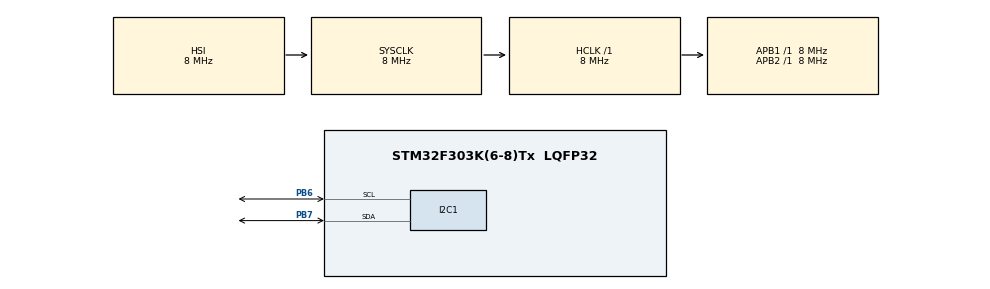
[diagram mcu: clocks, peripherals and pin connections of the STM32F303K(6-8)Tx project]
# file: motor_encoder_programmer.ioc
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I2C1.Timing=0x00201D2B
Mcu.Family=STM32F3
Mcu.Name=STM32F303K(6-8)Tx
Mcu.Package=LQFP32
NVIC.PriorityGroup=NVIC_PRIORITYGROUP_4
PA13.Mode=Serial_Wire
PA13.Signal=SYS_JTMS-SWDIO
PA14.Mode=Serial_Wire
PA14.Signal=SYS_JTCK-SWCLK
PB6.GPIO_Pu=GPIO_PULLUP
PB6.Mode=I2C
PB6.Signal=I2C1_SCL
PB7.GPIO_Pu=GPIO_PULLUP
PB7.Mode=I2C
PB7.Signal=I2C1_SDA
ProjectManager.HeapSize=0x200
ProjectManager.StackSize=0x400
ProjectManager.TargetToolchain=STM32CubeIDE
RCC.AHBFreq_Value=8000000
RCC.APB1Freq_Value=8000000
RCC.APB2Freq_Value=8000000
RCC.CortexFreq_Value=8000000
RCC.HSE_VALUE=8000000
RCC.HSI_VALUE=8000000
RCC.SYSCLKFreq_VALUE=8000000
board=custom

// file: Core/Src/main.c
/* USER CODE BEGIN Header */
/**
 ******************************************************************************
 * @file           : main.c
 * @brief          : Main program body
 ******************************************************************************
 * @attention
 *
 * Copyright (c) 2025 STMicroelectronics.
 * All rights reserved.
 *
 * This software is licensed under terms that can be found in the LICENSE file
 * in the root directory of this software component.
 * If no LICENSE file comes with this software, it is provided AS-IS.
 *
 ******************************************************************************
 */
/* USER CODE END Header */
#include "main.h"

/* USER CODE BEGIN Includes */
#include <string.h>
#include <stdlib.h>
/* USER CODE END Includes */

I2C_HandleTypeDef hi2c1;

void SystemClock_Config(void);
static void MX_GPIO_Init(void);
static void MX_I2C1_Init(void);
/* USER CODE BEGIN PFP */
HAL_StatusTypeDef i2c_Write_Encoder(I2C_HandleTypeDef *hi2c, uint16_t DevAddress, uint8_t MemAddress, uint8_t *pData, uint16_t len);  // <-- Add this line here
HAL_StatusTypeDef i2c_Read_Encoder(I2C_HandleTypeDef *hi2c, uint16_t DevAddress, uint8_t regAddress, uint8_t *pData, uint16_t len);
/* USER CODE END PFP */

int main(void)
{

  /* MCU Configuration--------------------------------------------------------*/

  /* Reset of all peripherals, Initializes the Flash interface and the Systick. */
   HAL_Init();

  /* Configure the system clock */
  SystemClock_Config();

  /* Initialize all configured peripherals */
  MX_GPIO_Init();
  MX_I2C1_Init();
  /* USER CODE BEGIN 2 */
	//const char wmsg[]="WeloveSTM32!";

  	uint8_t angle_data[] = {0x00, 0x00}; //Angle data buffer, read angle data into this buffer and also write to registers with this buffer for programming
  	uint8_t rmsg[20]; //received message buffer, randomly used

	//HAL i2c notes:
	//address of encoder device is 0110110, but we shift it to left because the transmit and receive functions require that. So we are left with 0x6C
	//Argument to right of 0x6C is the register address, see the register description in onenote.
  	//After reading from registers, the register address is incremented except for these registers: ANGLE, RAW ANGLE and MAGNITUDE Registers
  	//If you read from the ANGLE register (0x0E,0X0F), you get a decimal from 0 to 4095, 0x000 to 0xFFF in Hex (4096 total values). You have to scale that into 0 to 360.
	//i2c_Write_Encoder(&hi2c1, 0x6C, 0x08, (uint8_t*)data, sizeof(data) / sizeof(data[0]));

  	//Readout contents of registers
	i2c_Read_Encoder(&hi2c1, 0x6C, 0x00, (uint8_t*)rmsg, 1); //ZMCO, amount of times programmed angle
	i2c_Read_Encoder(&hi2c1, 0x6C, 0x01, (uint8_t*)rmsg, 2); //ZPOS, starting pos
	i2c_Read_Encoder(&hi2c1, 0x6C, 0x03, (uint8_t*)rmsg, 2); //MPOS, stop pos
	i2c_Read_Encoder(&hi2c1, 0x6C, 0x05, (uint8_t*)rmsg, 2); //MANG, maximum angle
	i2c_Read_Encoder(&hi2c1, 0x6C, 0x07, (uint8_t*)rmsg, 2); //Conf, configuration register
	i2c_Read_Encoder(&hi2c1, 0x6C, 0x0C, (uint8_t*)rmsg, 2); //Raw Angle
	i2c_Read_Encoder(&hi2c1, 0x6C, 0x0E, (uint8_t*)rmsg, 2); //Angle
	i2c_Read_Encoder(&hi2c1, 0x6C, 0x0B, (uint8_t*)rmsg, 1); //Status
	i2c_Read_Encoder(&hi2c1, 0x6C, 0x1A, (uint8_t*)rmsg, 1); //AGC, Automatic Gain Control, The AGC range is reduced to 0-128 counts in 3.3V mode.
	i2c_Read_Encoder(&hi2c1, 0x6C, 0x1B, (uint8_t*)rmsg, 2); //Magnitude: magnitude value of the internal CORDIC

//	//Angle Programming through I2C interface (Option A in datasheet)
//	//Run in debug mode, make sure to do the 3.3V wiring in fig.  38
//	//Turn angle to starting position
//	i2c_Read_Encoder(&hi2c1, 0x6C, 0x0C, (uint8_t*)angle_data, 2); //Read From starting position Raw Angle, store result in first two bytes of angle_data
//	i2c_Write_Encoder(&hi2c1, 0x6C, 0x01, (uint8_t*)angle_data, 2); //Write the starting position raw angle into ZPOS register
//	//Now rotate the magnet to the stop position
//	i2c_Read_Encoder(&hi2c1, 0x6C, 0x0C, (uint8_t*)angle_data, 2); //Read From starting position Raw Angle, store result in first two bytes of angle_data
//	i2c_Write_Encoder(&hi2c1, 0x6C, 0x03, (uint8_t*)angle_data, 2); //Write the starting position raw angle into MPOS register
//	//Burning the settings to "permanently" program the magnetic encoder.
//	uint8_t command_buffer[] = {0x00, 0x00, 0x00};
//	command_buffer[0] = 0x80; //BURN_ANGLE command
//	i2c_Write_Encoder(&hi2c1, 0x6C, 0xFF, (uint8_t*)command_buffer, 1); //Perform a BURN_ANGLE command by writing 0x80 value into 0xFF register
//	//Verify burn command
//	memcpy(command_buffer, ((uint8_t[3]){0x01, 0x11, 0x10}), 3 * sizeof(uint8_t)); //load the buffer with 3 commands, replaces the entire buffer
//	i2c_Write_Encoder(&hi2c1, 0x6C, 0xFF, (uint8_t*)command_buffer, 3); //Writing these 3 commands sequentially into 0xFF register to load actual OTP non-volatile memory content
//	//Read ZPOS and MPOS registers to verify the BURN_ANGLE command was successful
//	i2c_Read_Encoder(&hi2c1, 0x6C, 0x01, (uint8_t*)rmsg, 2); //ZPOS, starting pos
//	i2c_Read_Encoder(&hi2c1, 0x6C, 0x03, (uint8_t*)rmsg, 2); //MPOS, stop pos
//	//Might want to do power up cycle and reread the ZPOS and MPOS registers again to make sure they match with new positions

	//Programming to turn on PWM mode by modifying CONF register on magnetic encoder.
	i2c_Read_Encoder(&hi2c1, 0x6C, 0x07, (uint8_t*)rmsg, 2);
	i2c_Write_Encoder(&hi2c1, 0x6C, 0x01, (uint8_t*)angle_data, 2);
  /* USER CODE END 2 */

  /* Infinite loop */
	while (1)
	{

	}
}

void SystemClock_Config(void)
{
  RCC_OscInitTypeDef RCC_OscInitStruct = {0};
  RCC_ClkInitTypeDef RCC_ClkInitStruct = {0};
  RCC_PeriphCLKInitTypeDef PeriphClkInit = {0};

  /** Initializes the RCC Oscillators according to the specified parameters
  * in the RCC_OscInitTypeDef structure.
  */
  RCC_OscInitStruct.OscillatorType = RCC_OSCILLATORTYPE_HSI;
  RCC_OscInitStruct.HSIState = RCC_HSI_ON;
  RCC_OscInitStruct.HSICalibrationValue = RCC_HSICALIBRATION_DEFAULT;
  RCC_OscInitStruct.PLL.PLLState = RCC_PLL_NONE;
  if (HAL_RCC_OscConfig(&RCC_OscInitStruct) != HAL_OK)
  {
    Error_Handler();
  }

  /** Initializes the CPU, AHB and APB buses clocks
  */
  RCC_ClkInitStruct.ClockType = RCC_CLOCKTYPE_HCLK|RCC_CLOCKTYPE_SYSCLK
                              |RCC_CLOCKTYPE_PCLK1|RCC_CLOCKTYPE_PCLK2;
  RCC_ClkInitStruct.SYSCLKSource = RCC_SYSCLKSOURCE_HSI;
  RCC_ClkInitStruct.AHBCLKDivider = RCC_SYSCLK_DIV1;
  RCC_ClkInitStruct.APB1CLKDivider = RCC_HCLK_DIV1;
  RCC_ClkInitStruct.APB2CLKDivider = RCC_HCLK_DIV1;

  if (HAL_RCC_ClockConfig(&RCC_ClkInitStruct, FLASH_LATENCY_0) != HAL_OK)
  {
    Error_Handler();
  }
  PeriphClkInit.PeriphClockSelection = RCC_PERIPHCLK_I2C1;
  PeriphClkInit.I2c1ClockSelection = RCC_I2C1CLKSOURCE_HSI;
  if (HAL_RCCEx_PeriphCLKConfig(&PeriphClkInit) != HAL_OK)
  {
    Error_Handler();
  }
}

static void MX_I2C1_Init(void)
{

  hi2c1.Instance = I2C1;
  hi2c1.Init.Timing = 0x00201D2B;
  hi2c1.Init.OwnAddress1 = 0;
  hi2c1.Init.AddressingMode = I2C_ADDRESSINGMODE_7BIT;
  hi2c1.Init.DualAddressMode = I2C_DUALADDRESS_DISABLE;
  hi2c1.Init.OwnAddress2 = 0;
  hi2c1.Init.OwnAddress2Masks = I2C_OA2_NOMASK;
  hi2c1.Init.GeneralCallMode = I2C_GENERALCALL_DISABLE;
  hi2c1.Init.NoStretchMode = I2C_NOSTRETCH_DISABLE;
  if (HAL_I2C_Init(&hi2c1) != HAL_OK)
  {
    Error_Handler();
  }

  /** Configure Analogue filter
  */
  if (HAL_I2CEx_ConfigAnalogFilter(&hi2c1, I2C_ANALOGFILTER_ENABLE) != HAL_OK)
  {
    Error_Handler();
  }

  /** Configure Digital filter
  */
  if (HAL_I2CEx_ConfigDigitalFilter(&hi2c1, 0) != HAL_OK)
  {
    Error_Handler();
  }

}

static void MX_GPIO_Init(void)
{

  /* GPIO Ports Clock Enable */
  __HAL_RCC_GPIOA_CLK_ENABLE();
  __HAL_RCC_GPIOB_CLK_ENABLE();

}

/* USER CODE BEGIN 4 */
HAL_StatusTypeDef i2c_Read_Encoder(I2C_HandleTypeDef *hi2c, uint16_t DevAddress, uint8_t regAddress, uint8_t *pData, uint16_t len) {
  HAL_StatusTypeDef returnValue;
  uint8_t addr[1];

  /* We compute the MSB and LSB parts of the memory address */
  addr[0] = (uint8_t) (regAddress);

  /* First we send the memory location address where start reading data */
  returnValue = HAL_I2C_Master_Transmit(hi2c, DevAddress, addr, 1, HAL_MAX_DELAY);
  if(returnValue != HAL_OK)
    return returnValue;

  /* Next we can retrieve the data from EEPROM */
  returnValue = HAL_I2C_Master_Receive(hi2c, DevAddress, pData, len, HAL_MAX_DELAY);

  return returnValue;
}

HAL_StatusTypeDef i2c_Write_Encoder(I2C_HandleTypeDef *hi2c, uint16_t DevAddress, uint8_t regAddress, uint8_t *pData, uint16_t len)
{
	HAL_StatusTypeDef returnValue;
	uint8_t *data;

	data = (uint8_t*)malloc(sizeof(uint8_t));
	/*We compute the MSB and LSB parts of the memory address*/
	data[0]=(uint8_t)(regAddress);

	/*And copy the content of the pData array in the temporary buffer*/
	memcpy(data+1,pData,len); //inserts data one slot after the register address

	/*We are now ready to transfer the buffer over the I2C bus*/
	returnValue=HAL_I2C_Master_Transmit(hi2c,DevAddress,data,len+1,HAL_MAX_DELAY);
	if(returnValue!=HAL_OK)
		return returnValue;

	free(data);
	/*We wait until the EEPROM effectively stores data in memory*/
	while(HAL_I2C_Master_Transmit(hi2c,DevAddress,0,0,HAL_MAX_DELAY)!=HAL_OK);//peripheral can only accept the transmission once it finishes doing what it does

	return HAL_OK;
}
/* USER CODE END 4 */

void Error_Handler(void)
{
	__disable_irq();
	while (1)
	{
	}
}
